AUTOSAR XML (schema 00052)
package /apd/AdaptiveApplicationSwComponentTypes
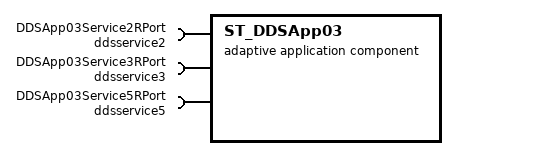
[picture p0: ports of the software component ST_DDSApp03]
  adaptive application sw component type ST_DDSApp03
    require port DDSApp03Service2RPort: required-interface=ddsservice2
    require port DDSApp03Service3RPort: required-interface=ddsservice3
    require port DDSApp03Service5RPort: required-interface=ddsservice5
package /apd/Executables
  executable ST_DDSApp03: category=APPLICATION_LEVEL, minimum-timer-granularity=1000
    root sw component prototype ST_DDSApp03Root: application-type=ST_DDSApp03
